# f280015x_mcanss_regs register map
Vendor: Texas Instruments
Peripheral module from a debugger description file (folder C2000).
Address unit: 16 bits
Registers are 32-bit, read-write, no defined reset value unless marked. A register's access mark holds for its fields unless they carry their own. Offsets are as the file gives them; lines under a group give offsets from that group; [hi:lo] are bit positions; {n}, {i} and the like mark numbered series; 'fields as' and 'values as' point back to an identical list; <NAME> marks a mode.

## MCANSS_REGS — MCANSS Registers
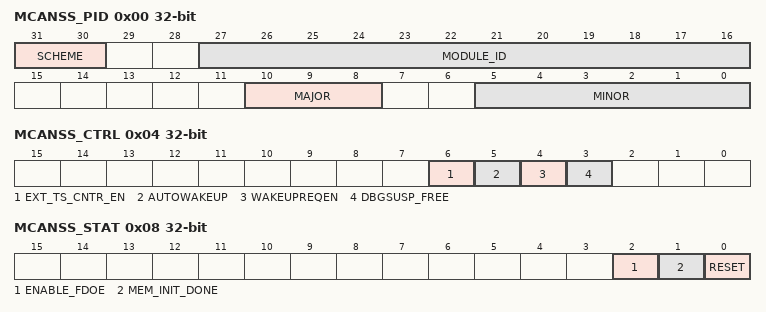
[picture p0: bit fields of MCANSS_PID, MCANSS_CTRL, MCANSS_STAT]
0x00 MCANSS_PID ro — MCAN Subsystem Revision Register
  [31:30] SCHEME — PID Register Scheme
  [27:16] MODULE_ID — Module Identification Number
  [10:8] MAJOR — Major Revision
  [5:0] MINOR — Minor Revision
0x04 MCANSS_CTRL — MCAN Subsystem Control Register
  [6] EXT_TS_CNTR_EN — External Timestamp Counter Enable
  [5] AUTOWAKEUP — Automatic Wakeup Enable
  [4] WAKEUPREQEN — Wakeup Request Enable
  [3] DBGSUSP_FREE — Debug Suspend Free
0x08 MCANSS_STAT ro — MCAN Subsystem Status Register
  [2] ENABLE_FDOE — Flexible Datarate Operation Enable
  [1] MEM_INIT_DONE — Memory Initialization Done
  [0] RESET — Soft Reset Status
0x0C MCANSS_ICS — MCAN Subsystem Interrupt Clear Shadow Register
  [0] EXT_TS_CNTR_OVFL — External Timestamp Counter Overflow Interrupt Status Clear
0x10 MCANSS_IRS — MCAN Subsystem Interrupt Raw Satus Register
  [0] EXT_TS_CNTR_OVFL — External Timestamp Counter Overflow Interrupt Status
0x14 MCANSS_IECS — MCAN Subsystem Interrupt Enable Clear Shadow Register
  [0] EXT_TS_CNTR_OVFL — External Timestamp Counter Overflow Interrupt Enable Clear
0x18 MCANSS_IE — MCAN Subsystem Interrupt Enable Register
  [0] EXT_TS_CNTR_OVFL — External Timestamp Counter Overflow Interrupt Enable
0x1C MCANSS_IES ro — MCAN Subsystem Interrupt Enable Status
  [0] EXT_TS_CNTR_OVFL — External Timestamp Counter Overflow Interrupt Enable Status
0x20 MCANSS_EOI — MCAN Subsystem End of Interrupt
  [7:0] EOI — External Timestamp Counter Overflow End of Interrupt
0x24 MCANSS_EXT_TS_PRESCALER — MCAN Subsystem External Timestamp Prescaler 0
  [23:0] PRESCALER — External Timestamp Prescaler
0x28 MCANSS_EXT_TS_UNSERVICED_INTR_CNTR ro — MCAN Subsystem External Timestamp Unserviced Interrupts Counter
  [4:0] EXT_TS_INTR_CNTR — External Timestamp Counter Unserviced Rollover Interrupts
